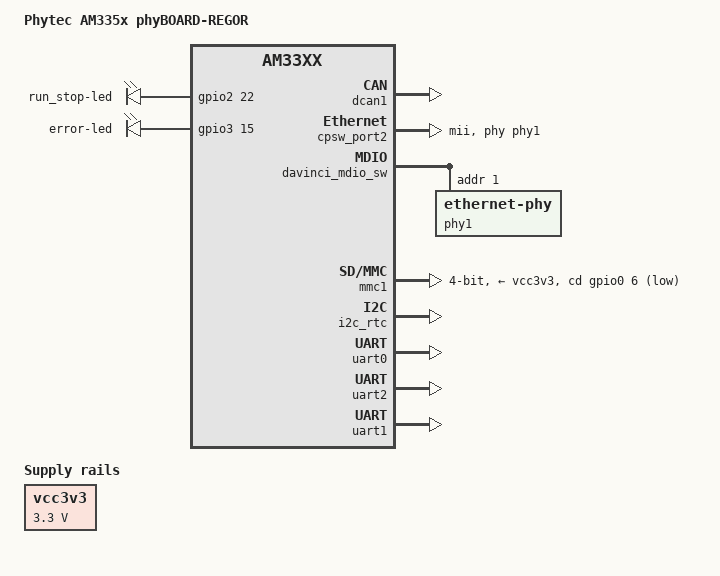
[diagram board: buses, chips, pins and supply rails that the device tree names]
/ {
	model = "Phytec AM335x phyBOARD-REGOR";
	compatible = "phytec,am335x-regor", "phytec,am335x-phycore-som", "ti,am33xx";
	vcc3v3: fixedregulator@1 {
		compatible = "regulator-fixed";
		regulator-name = "vcc3v3";
		regulator-min-microvolt = <3300000>;
		regulator-max-microvolt = <3300000>;
		regulator-boot-on;
	};
	user_leds: user-leds {
		compatible = "gpio-leds";
		pinctrl-names = "default";
		pinctrl-0 = <&user_leds_pins>;
		run_stop-led {
			gpios = <&gpio2 22 GPIO_ACTIVE_HIGH>;
			linux,default-trigger = "gpio";
			default-state = "off";
		};
		error-led {
			gpios = <&gpio3 15 GPIO_ACTIVE_HIGH>;
			linux,default-trigger = "gpio";
			default-state = "off";
		};
	};
};
&am33xx_pinmux {
	user_leds_pins: pinmux-user-leds-pins {
		pinctrl-single,pins = <
			AM33XX_PADCONF(AM335X_PIN_LCD_VSYNC, PIN_OUTPUT_PULLDOWN, MUX_MODE7)	 
			AM33XX_PADCONF(AM335X_PIN_MCASP0_FSX, PIN_OUTPUT_PULLDOWN, MUX_MODE7)	 
		>;
	};
};
&am33xx_pinmux {
	dcan1_pins: pinmux-dcan1-pins {
		pinctrl-single,pins = <
			AM33XX_PADCONF(AM335X_PIN_UART0_CTSN, PIN_OUTPUT_PULLUP, MUX_MODE2)	 
			AM33XX_PADCONF(AM335X_PIN_UART0_RTSN, PIN_INPUT_PULLUP, MUX_MODE2)	 
		>;
	};
};
&dcan1 {
	pinctrl-names = "default";
	pinctrl-0 = <&dcan1_pins>;
	status = "okay";
};
&am33xx_pinmux {
	ethernet1_pins: pinmux-ethernet1-pins {
		pinctrl-single,pins = <
			AM33XX_PADCONF(AM335X_PIN_GPMC_A0, PIN_OUTPUT, MUX_MODE1)		 
			AM33XX_PADCONF(AM335X_PIN_GPMC_A1, PIN_INPUT_PULLDOWN, MUX_MODE1)	 
			AM33XX_PADCONF(AM335X_PIN_GPMC_A2, PIN_OUTPUT, MUX_MODE1)		 
			AM33XX_PADCONF(AM335X_PIN_GPMC_A3, PIN_OUTPUT, MUX_MODE1)		 
			AM33XX_PADCONF(AM335X_PIN_GPMC_A4, PIN_OUTPUT, MUX_MODE1)		 
			AM33XX_PADCONF(AM335X_PIN_GPMC_A5, PIN_OUTPUT, MUX_MODE1)		 
			AM33XX_PADCONF(AM335X_PIN_GPMC_A6, PIN_INPUT_PULLDOWN, MUX_MODE1)	 
			AM33XX_PADCONF(AM335X_PIN_GPMC_A7, PIN_INPUT_PULLDOWN, MUX_MODE1)	 
			AM33XX_PADCONF(AM335X_PIN_GPMC_A8, PIN_INPUT_PULLDOWN, MUX_MODE1)	 
			AM33XX_PADCONF(AM335X_PIN_GPMC_A9, PIN_INPUT_PULLDOWN, MUX_MODE1)	  
			AM33XX_PADCONF(AM335X_PIN_GPMC_A10, PIN_INPUT_PULLDOWN, MUX_MODE1)	 
			AM33XX_PADCONF(AM335X_PIN_GPMC_A11, PIN_INPUT_PULLDOWN, MUX_MODE1)	 
			AM33XX_PADCONF(AM335X_PIN_GPMC_WPN, PIN_INPUT_PULLDOWN, MUX_MODE1)	 
			AM33XX_PADCONF(AM335X_PIN_GPMC_BEN1, PIN_INPUT_PULLDOWN, MUX_MODE1)	 
		>;
	};
};
&cpsw_port2 {
	status = "okay";
	phy-handle = <&phy1>;
	phy-mode = "mii";
	ti,dual-emac-pvid = <2>;
};
&davinci_mdio_sw {
	phy1: ethernet-phy@1 {
		reg = <1>;
	};
};
&mac_sw {
	pinctrl-names = "default";
	pinctrl-0 = <&ethernet0_pins &ethernet1_pins>;
};
&am33xx_pinmux {
	pinctrl-names = "default";
	pinctrl-0 = <&user_gpios_pins>;
	user_gpios_pins: pinmux-user-gpios-pins {
		pinctrl-single,pins = <
			AM33XX_PADCONF(AM335X_PIN_GPMC_AD11, PIN_INPUT, MUX_MODE7)		 
			AM33XX_PADCONF(AM335X_PIN_GPMC_AD10, PIN_INPUT, MUX_MODE7)		 
			AM33XX_PADCONF(AM335X_PIN_GPMC_AD9, PIN_INPUT, MUX_MODE7)		 
			AM33XX_PADCONF(AM335X_PIN_GPMC_AD8, PIN_INPUT, MUX_MODE7)		 
			AM33XX_PADCONF(AM335X_PIN_GPMC_AD15, PIN_OUTPUT, MUX_MODE7)		 
			AM33XX_PADCONF(AM335X_PIN_GPMC_AD14, PIN_OUTPUT, MUX_MODE7)		 
			AM33XX_PADCONF(AM335X_PIN_GPMC_AD13, PIN_OUTPUT, MUX_MODE7)		 
			AM33XX_PADCONF(AM335X_PIN_GPMC_AD12, PIN_OUTPUT, MUX_MODE7)		 
		>;
	};
};
&am33xx_pinmux {
	mmc1_pins: pinmux-mmc1-pins {
		pinctrl-single,pins = <
			AM33XX_PADCONF(AM335X_PIN_MMC0_DAT3, PIN_INPUT_PULLUP, MUX_MODE0)
			AM33XX_PADCONF(AM335X_PIN_MMC0_DAT2, PIN_INPUT_PULLUP, MUX_MODE0)
			AM33XX_PADCONF(AM335X_PIN_MMC0_DAT1, PIN_INPUT_PULLUP, MUX_MODE0)
			AM33XX_PADCONF(AM335X_PIN_MMC0_DAT0, PIN_INPUT_PULLUP, MUX_MODE0)
			AM33XX_PADCONF(AM335X_PIN_MMC0_CLK, PIN_INPUT_PULLUP, MUX_MODE0)
			AM33XX_PADCONF(AM335X_PIN_MMC0_CMD, PIN_INPUT_PULLUP, MUX_MODE0)
			AM33XX_PADCONF(AM335X_PIN_SPI0_CS1, PIN_INPUT_PULLUP, MUX_MODE7)	 
		>;
	};
};
&mmc1 {
	vmmc-supply = <&vcc3v3>;
	bus-width = <4>;
	pinctrl-names = "default";
	pinctrl-0 = <&mmc1_pins>;
	cd-gpios = <&gpio0 6 GPIO_ACTIVE_LOW>;
	status = "okay";
};
&i2c_rtc {
	status = "okay";
};
&am33xx_pinmux {
	uart0_pins: pinmux-uart0-pins {
		pinctrl-single,pins = <
			AM33XX_PADCONF(AM335X_PIN_UART0_RXD, PIN_INPUT_PULLUP, MUX_MODE0)
			AM33XX_PADCONF(AM335X_PIN_UART0_TXD, PIN_OUTPUT_PULLDOWN, MUX_MODE0)
		>;
	};
	uart2_pins: pinmux-uart2-pins {
		pinctrl-single,pins = <
			AM33XX_PADCONF(AM335X_PIN_MII1_TX_CLK, PIN_INPUT_PULLUP, MUX_MODE1)	 
			AM33XX_PADCONF(AM335X_PIN_MII1_RX_CLK, PIN_OUTPUT_PULLDOWN, MUX_MODE1)	 
		>;
	};
};
&uart0 {
	pinctrl-names = "default";
	pinctrl-0 = <&uart0_pins>;
	status = "okay";
};
&uart2 {
	pinctrl-names = "default";
	pinctrl-0 = <&uart2_pins>;
	status = "okay";
};
&am33xx_pinmux {
	uart1_rs485_pins: pinmux-uart1-rs485-pins {
		pinctrl-single,pins = <
			AM33XX_PADCONF(AM335X_PIN_UART1_RXD, PIN_INPUT_PULLUP, MUX_MODE0)
			AM33XX_PADCONF(AM335X_PIN_UART1_TXD, PIN_OUTPUT_PULLDOWN, MUX_MODE0)
			AM33XX_PADCONF(AM335X_PIN_UART1_RTSN, PIN_OUTPUT_PULLUP, MUX_MODE0)
		>;
	};
};
&uart1 {
	pinctrl-names = "default";
	pinctrl-0 = <&uart1_rs485_pins>;
	status = "okay";
	linux,rs485-enabled-at-boot-time;
};
